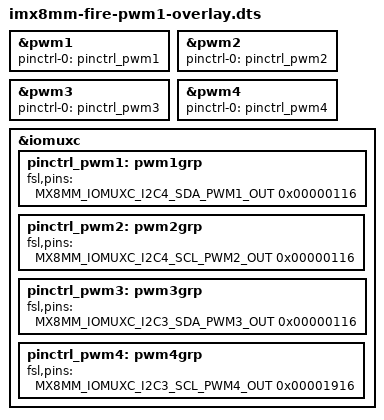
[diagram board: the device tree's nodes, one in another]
/*
 * Copyright (C) 2021 - All Rights Reserved by 
 * filename : imx8mm-fire-pwm1-overlay.dts
 * brief : Device Tree overlay for ebf imx8mm pwm1 device
 * author : embedfire
 * date : 2021-08-01 
 * version : A001
 */

/dts-v1/;
/plugin/;

#include "../imx8mm-pinfunc.h"
#include "dt-bindings/gpio/gpio.h"
#include "dt-bindings/clock/imx8mm-clock.h"

/ {
	fragment@0 {
		target= <&pwm1>;
        __overlay__{
			pinctrl-names = "default";
		    pinctrl-0 = <&pinctrl_pwm1>;
		    status = "okay";
		};
	};

	fragment@1 {
		target= <&pwm2>;
        __overlay__{
			pinctrl-names = "default";
		    pinctrl-0 = <&pinctrl_pwm2>;
		    status = "okay";
		};
	};

	fragment@2 {
		target= <&pwm3>;
        __overlay__{
			pinctrl-names = "default";
		    pinctrl-0 = <&pinctrl_pwm3>;
		    status = "okay";
		};
	};

	fragment@3 {
		target= <&pwm4>;
        __overlay__{
			pinctrl-names = "default";
		    pinctrl-0 = <&pinctrl_pwm4>;
		    status = "okay";
		};
	};
	
/*
*	pwm1-----GPIO5_IO21
*	pwm2-----GPIO5_IO20
*	pwm3-----GPIO5_IO19
*	pwm4-----GPIO5_IO18
*/
	fragment@4 {
		target= <&iomuxc>;
		__overlay__{
			pinctrl_pwm1: pwm1grp {
				fsl,pins = <
					MX8MM_IOMUXC_I2C4_SDA_PWM1_OUT             0x00000116
				>;
			};
			pinctrl_pwm2: pwm2grp {
				fsl,pins = <
					MX8MM_IOMUXC_I2C4_SCL_PWM2_OUT             0x00000116
				>;
			};
			pinctrl_pwm3: pwm3grp {
				fsl,pins = <
					MX8MM_IOMUXC_I2C3_SDA_PWM3_OUT             0x00000116
				>;
			};
			pinctrl_pwm4: pwm4grp {
				fsl,pins = <
					MX8MM_IOMUXC_I2C3_SCL_PWM4_OUT             0x00001916
				>;
			};
		};
	};
};

